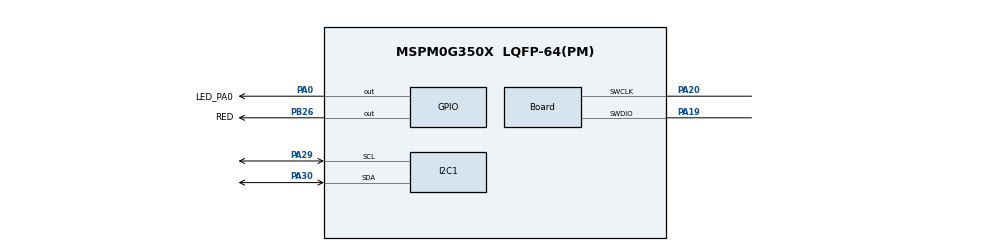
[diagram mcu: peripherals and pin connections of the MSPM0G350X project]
/**
 * @cliArgs --device "MSPM0G350X" --package "LQFP-64(PM)" --part "Default" --product "mspm0_sdk@2.00.01.00"
 * @versions {"tool":"1.20.0+3587"}
 */

/**
 * Import the modules used in this configuration.
 */
const GPIO          = scripting.addModule("/ti/driverlib/GPIO", {}, false);
const GPIO1         = GPIO.addInstance();
const GPIO2         = GPIO.addInstance();
const I2C           = scripting.addModule("/ti/driverlib/I2C", {}, false);
const I2C1          = I2C.addInstance();
const SYSCTL        = scripting.addModule("/ti/driverlib/SYSCTL");
const TIMER         = scripting.addModule("/ti/driverlib/TIMER", {}, false);
const TIMER1        = TIMER.addInstance();
const ProjectConfig = scripting.addModule("/ti/project_config/ProjectConfig");

/**
 * Write custom configuration values to the imported modules.
 */
GPIO1.port                          = "PORTA";
GPIO1.$name                         = "USER_GPIO";
GPIO1.associatedPins[0].$name       = "LED_PA0";
GPIO1.associatedPins[0].pin.$assign = "PA0";

const Board                       = scripting.addModule("/ti/driverlib/Board", {}, false);
Board.peripheral.$assign          = "DEBUGSS";
Board.peripheral.swclkPin.$assign = "PA20";
Board.peripheral.swdioPin.$assign = "PA19";

GPIO2.$name                         = "PORTB";
GPIO2.associatedPins[0].$name       = "RED";
GPIO2.associatedPins[0].pin.$assign = "PB26";

I2C1.$name                     = "I2C_0";
I2C1.basicEnableController     = true;
I2C1.peripheral.$assign        = "I2C1";
I2C1.peripheral.sdaPin.$assign = "PA30";
I2C1.peripheral.sclPin.$assign = "PA29";
I2C1.sdaPinConfig.$name        = "ti_driverlib_gpio_GPIOPinGeneric0";
I2C1.sclPinConfig.$name        = "ti_driverlib_gpio_GPIOPinGeneric1";

SYSCTL.clockTreeEn = true;

TIMER1.$name              = "TIMER_0";
TIMER1.timerPeriod        = "100 ms";
TIMER1.timerClkPrescale   = 100;
TIMER1.timerMode          = "PERIODIC_UP";
TIMER1.interrupts         = ["ZERO"];
TIMER1.peripheral.$assign = "TIMG0";

ProjectConfig.deviceSpin = "MSPM0G3507";
